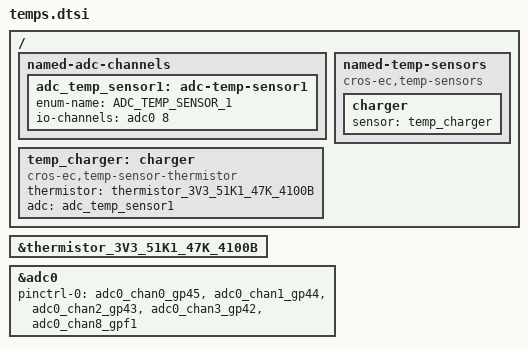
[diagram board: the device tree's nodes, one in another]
/* Copyright 2025 The ChromiumOS Authors
 * Use of this source code is governed by a BSD-style license that can be
 * found in the LICENSE file.
 */
#include <cros/thermistor/thermistor.dtsi>

/ {
	named-adc-channels {
		adc_temp_sensor1: adc-temp-sensor1 {
			enum-name = "ADC_TEMP_SENSOR_1";
			io-channels = <&adc0 8>;
		};
	};
	temp_charger: charger {
		compatible = "cros-ec,temp-sensor-thermistor";
		thermistor = <&thermistor_3V3_51K1_47K_4100B>;
		adc = <&adc_temp_sensor1>;
	};

	named-temp-sensors {
		compatible = "cros-ec,temp-sensors";
		charger {
			sensor = <&temp_charger>;
		};
	};
};

&thermistor_3V3_51K1_47K_4100B {
	status = "okay";
};

&adc0 {
	status = "okay";
	pinctrl-0 = <&adc0_chan0_gp45
		     &adc0_chan1_gp44
		     &adc0_chan2_gp43
		     &adc0_chan3_gp42
		     &adc0_chan8_gpf1>;
	pinctrl-names = "default";
};
